# nrf9120 register map
Vendor: Nordic Semiconductor; Series: nrf91; File version: 1
CPU: CM33 r0p4, little endian, MPU, FPU, 3 interrupt priority bits, 69 interrupts
Registers are 32-bit, read-write, reset 0x0 unless marked. A register's access mark holds for its fields unless they carry their own. Offsets are from the block's base; [hi:lo] are bit positions; lines under a group give offsets from that group; {n}, {i} and the like mark numbered series.

## NVMC_NS — Non-volatile memory controller 0
Base 0x40039000; alternate view of APPROTECT_NS
Same registers: NVMC_S 0x50039000 (alternate view of APPROTECT_S)
0x400 READY ro reset 0x1 — Ready flag
  [0] READY — NVMC is ready or busy
    0=Busy (NVMC is busy (on-going write or erase operation)); 1=Ready (NVMC is ready)
0x408 READYNEXT ro reset 0x1 — Ready flag
  [0] READYNEXT — NVMC can accept a new write operation
    0=Busy (NVMC cannot accept any write operation); 1=Ready (NVMC is ready)
0x504 CONFIG — Configuration register
  [2:0] WEN — Program memory access mode. It is strongly recommended to only activate erase and write modes when they are actively used. Enabling write or erase will invalidate the cache and keep it invalidated.
    0=Ren (Read only access); 1=Wen (Write enabled); 2=Een (Erase enabled); 4=PEen (Partial erase enabled)
0x50C ERASEALL wo — Register for erasing all non-volatile user memory
  [0] ERASEALL — Erase all non-volatile memory including UICR registers. Note that erasing must be enabled by setting CONFIG.WEN = Een before the non-volatile memory can be erased.
    0=NoOperation; 1=Erase (Start chip erase)
0x51C ERASEPAGEPARTIALCFG reset 0xA — Register for partial erase configuration
  [6:0] DURATION — Duration of the partial erase in milliseconds
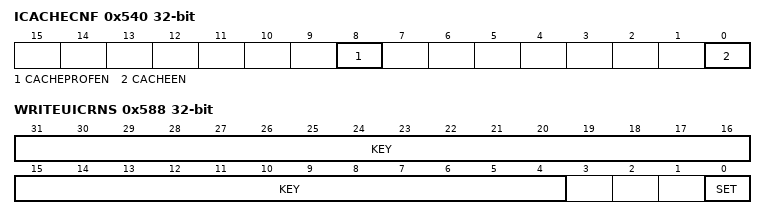
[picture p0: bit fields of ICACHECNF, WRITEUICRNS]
0x540 ICACHECNF — I-code cache configuration register
  [8] CACHEPROFEN — Cache profiling enable
    0=Disabled (Disable cache profiling); 1=Enabled (Enable cache profiling)
  [0] CACHEEN — Cache enable
    0=Disabled (Disable cache. Invalidates all cache entries.); 1=Enabled (Enable cache)
0x548 IHIT — I-code cache hit counter
  [31:0] HITS — Number of cache hits Write zero to clear
0x54C IMISS — I-code cache miss counter
  [31:0] MISSES — Number of cache misses Write zero to clear
0x584 CONFIGNS — Unspecified
  [1:0] WEN — Program memory access mode. It is strongly recommended to only activate erase and write modes when they are actively used. Enabling write or erase will invalidate the cache and keep it invalidated.
    0=Ren (Read only access); 1=Wen (Write enabled); 2=Een (Erase enabled)
0x588 WRITEUICRNS wo — Non-secure APPROTECT enable register
  [31:4] KEY — Key to write in order to validate the write operation
    0xAFBE5A7=Keyvalid (Key value)
  [0] SET — Allow non-secure code to set APPROTECT
    1=Set (Set value)

## VMC_NS — Volatile Memory controller 0
Base 0x4003A000
Same registers: VMC_S 0x5003A000
{0x600+0x10*i} RAM[{i}] (i=0..7) group — Unspecified
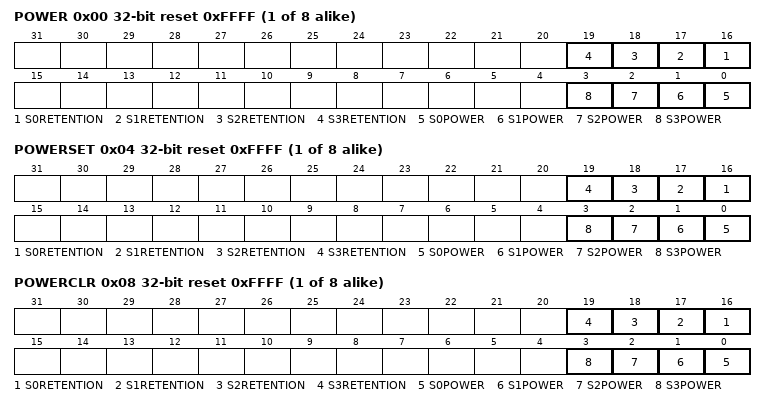
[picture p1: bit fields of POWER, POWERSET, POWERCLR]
  0x00 POWER reset 0xFFFF — Description cluster: RAMn power control register
    [all] fields
      0=Off; 1=On
    [n+16] S{n}RETENTION (n=0..3) — Keep retention on RAM section S{n} of RAM n when RAM section is switched off
    [n] S{n}POWER (n=0..3) — Keep RAM section S{n} of RAM n on or off in System ON mode
  0x04 POWERSET wo reset 0xFFFF — Description cluster: RAMn power control set register
    [all] fields
      1=On
    [n+16] S{n}RETENTION (n=0..3) — Keep retention on RAM section S{n} of RAM n when RAM section is switched off
    [n] S{n}POWER (n=0..3) — Keep RAM section S{n} of RAM n on or off in System ON mode
  0x08 POWERCLR wo reset 0xFFFF — Description cluster: RAMn power control clear register
    [all] fields
      1=Off
    [n+16] S{n}RETENTION (n=0..3) — Keep retention on RAM section S{n} of RAM n when RAM section is switched off
    [n] S{n}POWER (n=0..3) — Keep RAM section S{n} of RAM n on or off in System ON mode

## CC_HOST_RGF_S — CRYPTOCELL HOST_RGF interface
Base 0x50840000
0x1A38 HOST_CRYPTOKEY_SEL — AES hardware key select
  [1:0] HOST_CRYPTOKEY_SEL — Select the source of the HW key that is used by the AES engine
    0=K_DR (Use device root key K_DR from CRYPTOCELL AO power domain); 1=K_PRTL (Use hard-coded RTL key K_PRTL); 2=Session (Use provided session key)
0x1A4C HOST_IOT_KPRTL_LOCK — This write-once register is the K_PRTL lock register. When this register is set, K_PRTL cannot be used and a zeroed key will be used instead. The value of this register is saved in the CRYPTOCELL AO power domain.
  [0] HOST_IOT_KPRTL_LOCK — This register is the K_PRTL lock register. When this register is set, K_PRTL cannot be used and a zeroed key will be used instead. The value of this register is saved in the CRYPTOCELL AO power domain.
    0=Disabled (K_PRTL can be selected for use from register HOST_CRYPTOKEY_SEL); 1=Enabled (K_PRTL has been locked until next power-on reset (POR). If K_PRTL is selected anyway, a zeroed key will be used instead.)
0x1A50 HOST_IOT_KDR0 — This register holds bits 31:0 of K_DR. The value of this register is saved in the CRYPTOCELL AO power domain. Reading from this address returns the K_DR valid status indicating if K_DR is successfully retained.
  [31:0] HOST_IOT_KDR0 — Write: K_DR bits 31:0. Read: 0x00000000 when 128-bit K_DR key value is not yet retained in the CRYPTOCELL AO power domain. Read: 0x00000001 when 128-bit K_DR key value is successfully retained in the CRYPTOCELL AO power domain.
{0x1A50+4i} HOST_IOT_KDR{i} wo (i=1..3) — This register holds bits {32i+31}:{32i} of K_DR. The value of this register is saved in the CRYPTOCELL AO power domain.
  [31:0] HOST_IOT_KDR{i} — K_DR bits {32i+31}:{32i}
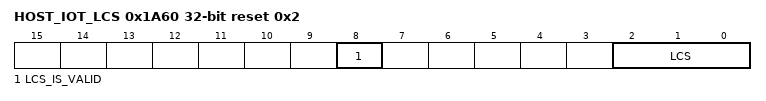
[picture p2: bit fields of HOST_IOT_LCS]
0x1A60 HOST_IOT_LCS reset 0x2 — Controls lifecycle state (LCS) for CRYPTOCELL subsystem
  [8] LCS_IS_VALID — Read-only field. Indicates if CRYPTOCELL LCS has been successfully configured since last reset.
    0=Invalid (Valid LCS not yet retained in the CRYPTOCELL AO power domain); 1=Valid LCS successfully retained in the CRYPTOCELL AO power domain
  [2:0] LCS — Lifecycle state value. This field is write-once per reset.
    0=Debug (CC310 operates in debug mode); 2=Secure (CC310 operates in secure mode)
